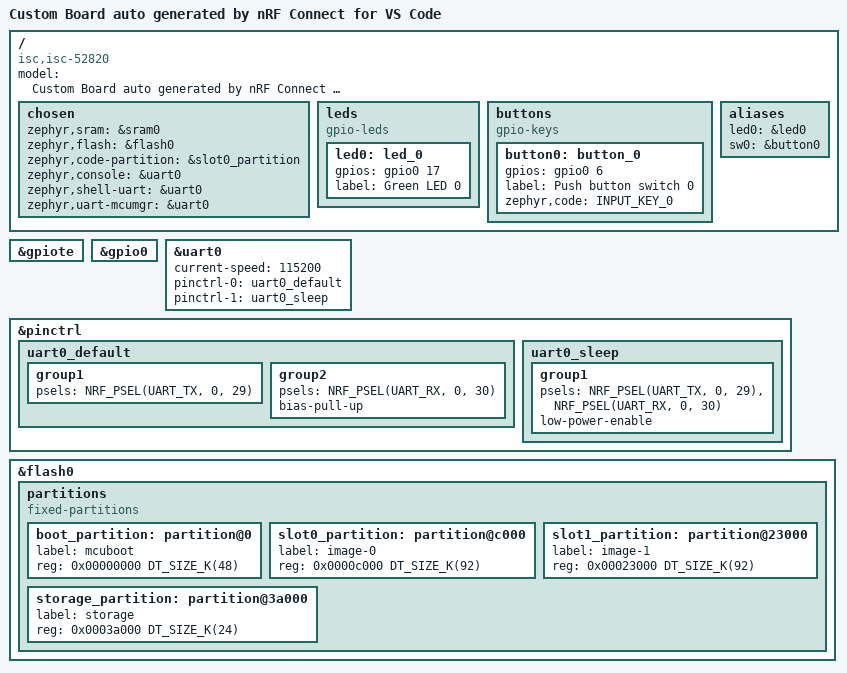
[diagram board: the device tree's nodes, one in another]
/dts-v1/;
#include <nordic/nrf52820_qdaa.dtsi>
#include "isc_52820-pinctrl.dtsi"

/ {
	model = "Custom Board auto generated by nRF Connect for VS Code";
	compatible = "isc,isc-52820";

	chosen {
		zephyr,sram = &sram0;
		zephyr,flash = &flash0;
		zephyr,code-partition = &slot0_partition;

		zephyr,console = &uart0;
		zephyr,shell-uart = &uart0;
		zephyr,uart-mcumgr = &uart0;
	};
	leds {
		compatible = "gpio-leds";
		led0: led_0 {
			gpios = <&gpio0 17 0>;
			label = "Green LED 0";
		};
	};
	buttons {
		compatible = "gpio-keys";
		button0: button_0 {
			// gpios = <&gpio0 6 (GPIO_ACTIVE_LOW)>;
			gpios = <&gpio0 6 (GPIO_ACTIVE_HIGH)>;
			label = "Push button switch 0";
			zephyr,code = <INPUT_KEY_0>;
		};
	};

	/* These aliases are provided for compatibility with samples */
	aliases {
		led0 = &led0;
		sw0 = &button0;
	};
};
&gpiote {
	status = "okay";
};

&gpio0 {
	status = "okay";
};
&uart0 {
	status = "okay";
	current-speed = <115200>;
	pinctrl-0 = <&uart0_default>;
	pinctrl-1 = <&uart0_sleep>;
	pinctrl-names = "default", "sleep";
};
&pinctrl {
	uart0_default: uart0_default {
		group1 {
			psels = <NRF_PSEL(UART_TX, 0, 29)>;
		};
		group2 {
			psels = <NRF_PSEL(UART_RX, 0, 30)>;
			bias-pull-up;
		};
	};

	uart0_sleep: uart0_sleep {
		group1 {
			psels = <NRF_PSEL(UART_TX, 0, 29)>,
					<NRF_PSEL(UART_RX, 0, 30)>;
			low-power-enable;
		};
	};
};

&flash0 {
	partitions {
		compatible = "fixed-partitions";
		#address-cells = <1>;
		#size-cells = <1>;

		boot_partition: partition@0 {
			label = "mcuboot";
			reg = <0x00000000 DT_SIZE_K(48)>;
		};

		slot0_partition: partition@c000 {
			label = "image-0";
			reg = <0x0000c000 DT_SIZE_K(92)>;
		};

		slot1_partition: partition@23000 {
			label = "image-1";
			reg = <0x00023000 DT_SIZE_K(92)>;
		};

		storage_partition: partition@3a000 {
			label = "storage";
			reg = <0x0003a000 DT_SIZE_K(24)>;
		};
	};
};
